# YTM32B1LE1 register map
Vendor: YTMicro; File version: 1.0
CPU: CM0PLUS r0p1, little endian, MPU, FPU, 2 interrupt priority bits
Registers are 32-bit, read-write, reset 0x0 unless marked. A register's access mark holds for its fields unless they carry their own. Offsets are from the block's base; [hi:lo] are bit positions; {n}, {i} and the like mark numbered series; <NAME> marks a mode.

## IPC — IP Control
Base 0x40065000; register names take the prefix IPC_
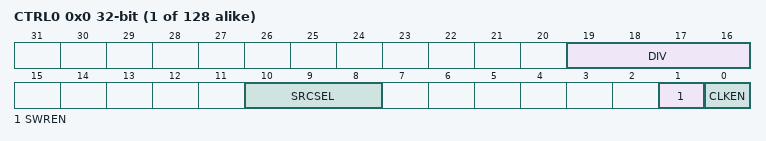
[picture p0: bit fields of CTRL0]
{0x0+4i} CTRL{i} (i=0..127)
  [19:16] DIV — The divider value = register value + 1.
  [10:8] SRCSEL
    0=No clock; 1=FIRC; 2=SIRC; 3=FXOSC; 5=LPO_CLK
  [1] SWREN — Not all modules support, please see \hyperref[ip-clock-control-tab]{Table 13.1 SWR column} for more information.
    0=Software reset is de-asserted; 1=Software reset is asserted
  [0] CLKEN — Not all modules support, please see \hyperref[ip-clock-control-tab]{Table 13.1 Bus Clock Enable column} for more information.
    0=IP clock is disabled; 1=IP clock is enabled

## RCU — Reset Control Unit of Micro-controller
Base 0x4007F000; register names take the prefix RCU_
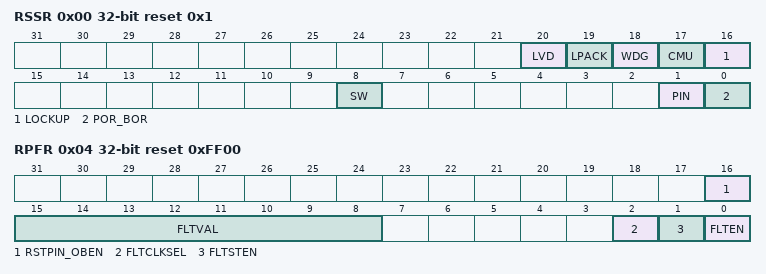
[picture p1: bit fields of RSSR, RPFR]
0x00 RSSR reset 0x1 — This register includes read-only status flags to indicate the source of the most recent reset. Multiple flags will be set if multiple reset events occur at the same time.
  [20] LVD — System reset caused by Low Voltage Detect.
    0=System reset not caused by Low Voltage Detect; 1=System reset caused by Low Voltage Detect
  [19] LPACK — System reset caused by Deepsleep/Standby acknowledge timeout. Indicates that after an attempt to enter Deepsleep/Standby mode, a reset has been caused by a failure of one or more peripherals to acknowledge.
    0=System reset not caused by Deepsleep/Standby acknowledge timeout; 1=System reset caused by Deepsleep/Standby acknowledge timeout
  [18] WDG
    0=System reset not caused by WDG; 1=System reset caused by WDG
  [17] CMU — System reset caused by Clock Monitor if CMURE is set.
    0=System reset not caused by CMU; 1=System reset caused by CMU
  [16] LOCKUP — System reset caused by ARM Core Lockup.
    0=System reset not caused by Lockup; 1=System reset caused by Lockup
  [8] SW — System reset caused by software to set SYSRESETREQ of ARM Core.
    0=System reset not caused by SW; 1=System reset caused by SW
  [1] PIN — System reset caused by RESET_b pin.
    0=System reset not caused by PIN; 1=System reset caused by PIN
  [0] POR_BOR — System reset caused by POR or BOR.
    0=System reset not caused by POR or BOR; 1=System reset caused by POR or BOR
0x04 RPFR reset 0xFF00 — This register controls the reset pin filter functions.
  [16] RSTPIN_OBEN — Enable bit of Reset pin output
    0=Not output low on reset pin when chip reset occurs; 1=Output low on reset pin when chip reset occurs
  [15:8] FLTVAL — FLTVAL control the filter counter value of filter clock cycles. 00000000b - Filter counter value is 0 00000001b - Filter counter value is 1 ... 11111111b - Filter counter value is 255
  [2] FLTCLKSEL — Select LPO_CLK and SIRC_CLK as Reset pin filter clock source
    0=Select LPO_CLK as Reset pin filter clock; 1=Select SIRC_CLK as Reset pin filter clock
  [1] FLTSTEN — Enable bit of Reset pin filter in Deepsleep and Standby mode, this bit should be set if filter need to be used in Deepsleep and Standby mode. This bit has no effect of reset pin filter in RUN mode
    0=Disable reset pin filter in Deepsleep and Standby mode; 1=Enable reset pin filter in Deepsleep and Standby mode if FLTEN is set
  [0] FLTEN — Enable bit of Reset pin filter, this bit should be set if filter need to be used.
    0=Disable reset pin filter; 1=Enable reset pin filter

## pTMR0 — Periodic timer
Base 0x40037000; register names take the prefix pTMR0_
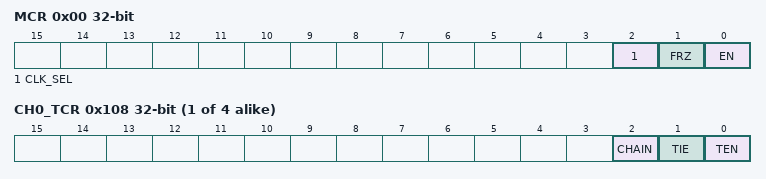
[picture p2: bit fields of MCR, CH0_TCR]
0x00 MCR
  [2] CLK_SEL — Select the timer clock source from pclk or func_clk.
    0=pTMR timer clock select pclk; 1=pTMR timer clock select func_clk, if select func_clk as ptmr timer clk, need to be met 2*func clk frequence < pclk frequence
  [1] FRZ — Allows the timers to be stopped when the device enters debug mode.
    0=pTMR continues to run in debug mode; 1=pTMR stops in debug mode
  [0] EN — Enable pTMR module.
    0=pTMR is disabled; 1=pTMR is enabled
{0x100+0x10*i} CH{i}_TSV (i=0..3) — Timer Start Value Register.
  [31:0] STVAL — This register set the timer start value. The timer will count down until it reaches 0, then it will generate an interrupt and loads the value again. Writing a new value to this register will not restart the timer, instead the value will be loaded once the timer expires. To abort the current cycle and start a timer period with the new value, the timer must be disabled and enabled again.
{0x104+0x10*i} CH{i}_TCV (i=0..3) — Timer Current Value Register
  [31:0] CVAL — This register stands for current timer value when user read this register. The value of this register will be frozen in debug mode if MCR[FRZ] is set.
{0x108+0x10*i} CH{i}_TCR (i=0..3) — Timer Control Register
  [2] CHAIN — When setting this bit, it will link multi-channel in sequence to combine a new bits counter, it just links the front channel.
    0=Chaining is disabled, channel timer runs independently; 1=Chaining is enabled
  [1] TIE — Enable interrupt when setting this bit.
    0=Disable timer interrupt of corresponding channel; 1=Enable timer interrupt of corresponding channel
  [0] TEN — Enable the timer of corresponding channel.
    0=Disable the timer of corresponding channel; 1=Enable the timer of corresponding channel
{0x10C+0x10*i} CH{i}_TFR (i=0..3) — Timer Flag Register
  [0] TIF — Hardware will set this bit as 1 when timer timeout occur, and writing logic 1 to this bit will clear this bit as 0.
    0=Timeout did not occur; 1=Timeout occurred
